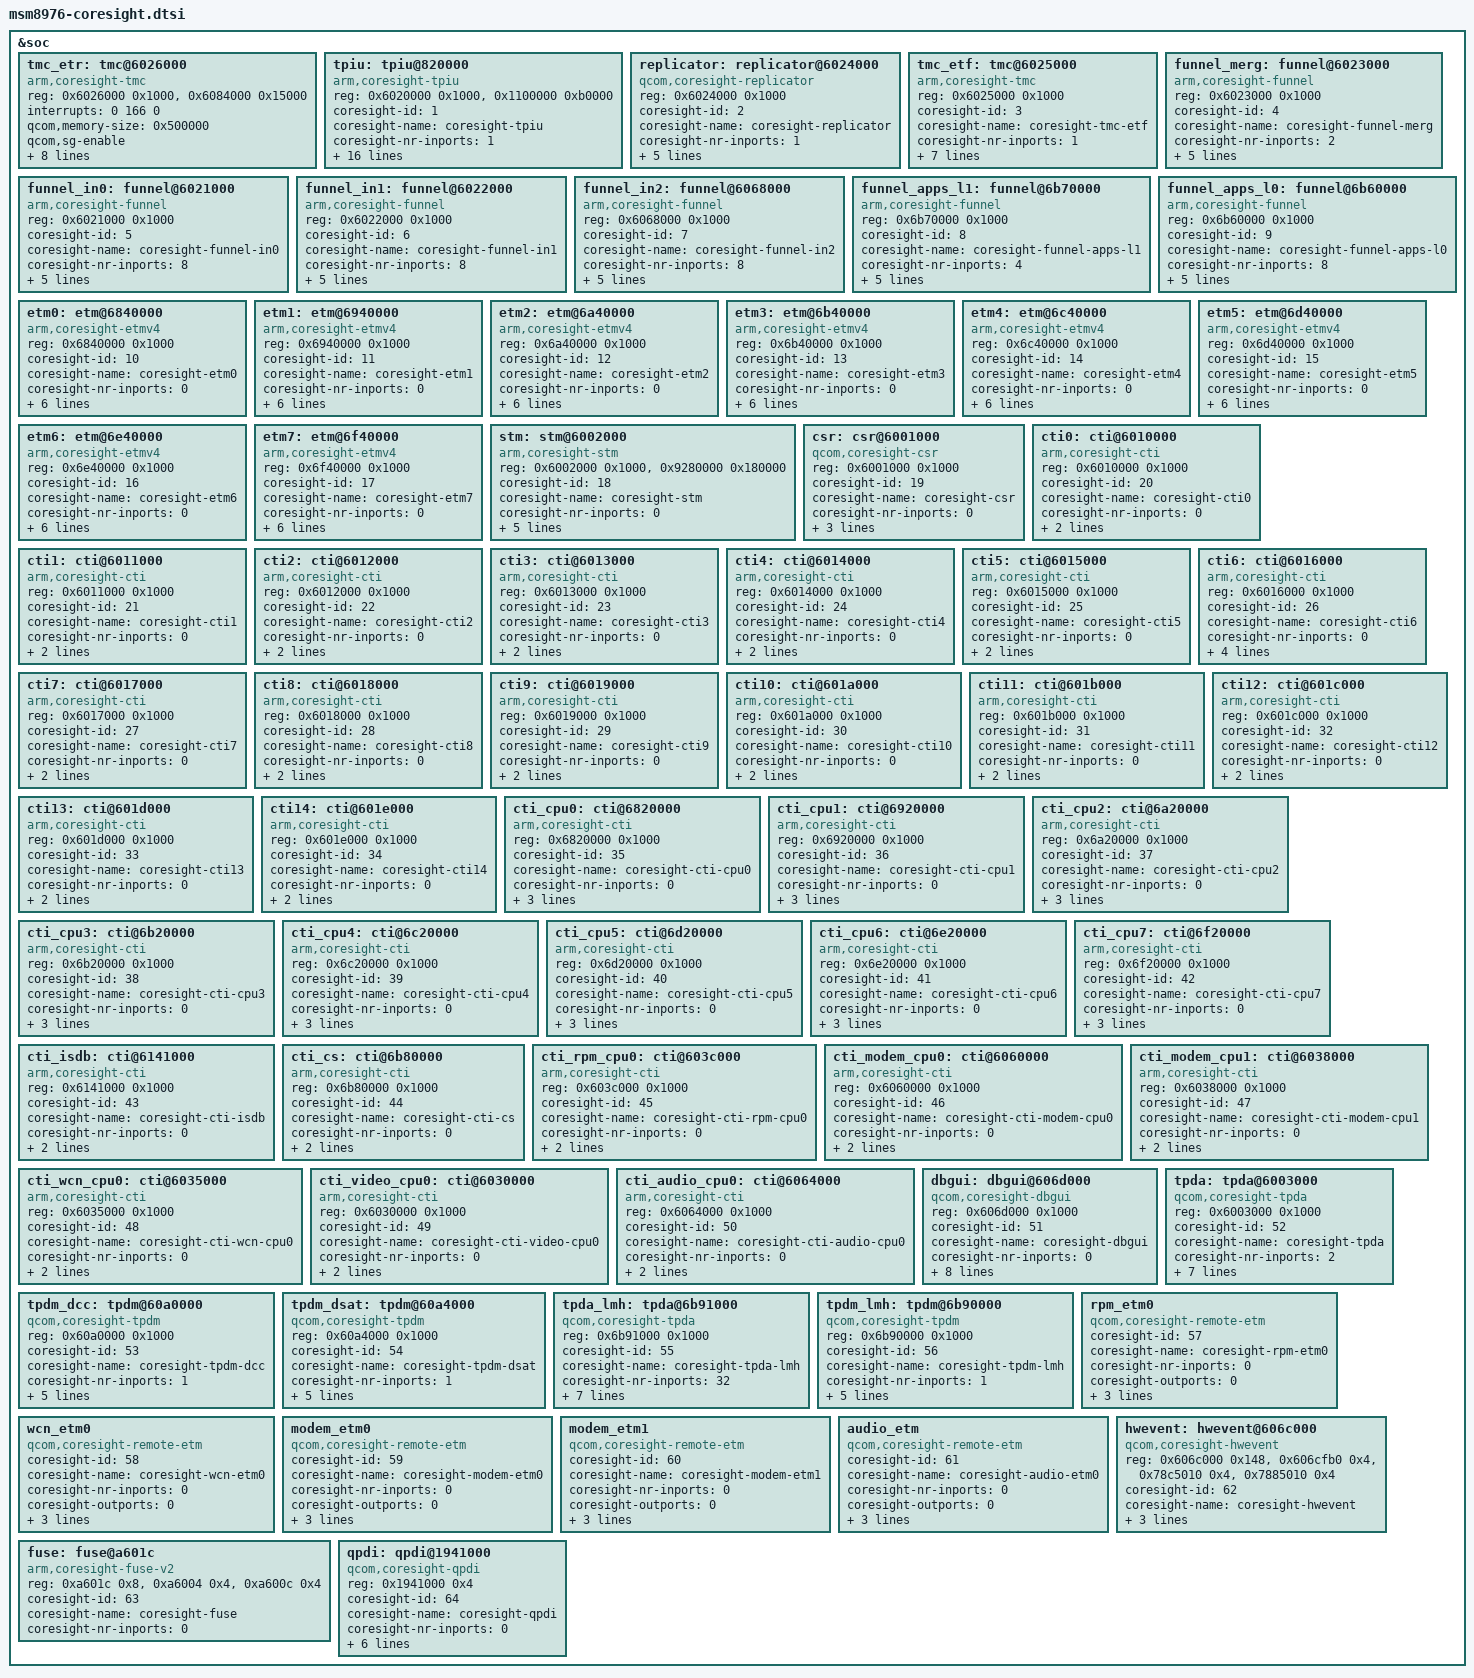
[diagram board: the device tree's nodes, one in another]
/* Copyright (c) 2015, The Linux Foundation. All rights reserved.
 *
 * This program is free software; you can redistribute it and/or modify
 * it under the terms of the GNU General Public License version 2 and
 * only version 2 as published by the Free Software Foundation.
 *
 * This program is distributed in the hope that it will be useful,
 * but WITHOUT ANY WARRANTY; without even the implied warranty of
 * MERCHANTABILITY or FITNESS FOR A PARTICULAR PURPOSE.  See the
 * GNU General Public License for more details.
 */

&soc {
	tmc_etr: tmc@6026000 {
		compatible = "arm,coresight-tmc";
		reg = <0x6026000 0x1000>,
		      <0x6084000 0x15000>;
		reg-names = "tmc-base", "bam-base";
		interrupts = <0 166 0>;
		interrupt-names = "byte-cntr-irq";

		qcom,memory-size = <0x500000>;
		qcom,sg-enable;
		coresight-default-sink;
		qcom,force-reg-dump;

		coresight-id = <0>;
		coresight-name = "coresight-tmc-etr";
		coresight-nr-inports = <1>;
		coresight-ctis = <&cti0 &cti8>;
		clocks = <&clock_gcc clk_qdss_clk>,
			 <&clock_gcc clk_qdss_a_clk>;
		clock-names = "core_clk", "core_a_clk";
	};

	tpiu: tpiu@820000 {
		compatible = "arm,coresight-tpiu";
		reg = <0x6020000 0x1000>,
		      <0x1100000 0xb0000>;
		reg-names = "tpiu-base", "nidnt-base";

		coresight-id = <1>;
		coresight-name = "coresight-tpiu";
		coresight-nr-inports = <1>;

		qcom,nidnthw;
		qcom,nidnt-swduart;
		qcom,nidnt-swdtrc;
		qcom,nidnt-jtag;
		qcom,nidnt-spmi;
		nidnt-gpio = <38>;
		nidnt-gpio-polarity = <1>;

		interrupts = <0 82 0>;
		interrupt-names = "nidnt-irq";

		vdd-supply = <&pm8950_l11>;
		qcom,vdd-voltage-level = <2950000 2950000>;
		qcom,vdd-current-level = <15000 400000>;

		vdd-io-supply = <&pm8950_l12>;
		qcom,vdd-io-voltage-level = <2950000 2950000>;
		qcom,vdd-io-current-level = <200 50000>;

		clocks = <&clock_gcc clk_qdss_clk>,
			 <&clock_gcc clk_qdss_a_clk>;
		clock-names = "core_clk", "core_a_clk";
	};

	replicator: replicator@6024000 {
		compatible = "qcom,coresight-replicator";
		reg = <0x6024000 0x1000>;
		reg-names = "replicator-base";

		coresight-id = <2>;
		coresight-name = "coresight-replicator";
		coresight-nr-inports = <1>;
		coresight-outports = <0 1>;
		coresight-child-list = <&tmc_etr &tpiu>;
		coresight-child-ports = <0 0>;
		clocks = <&clock_gcc clk_qdss_clk>,
			 <&clock_gcc clk_qdss_a_clk>;
		clock-names = "core_clk", "core_a_clk";
	};

	tmc_etf: tmc@6025000 {
		compatible = "arm,coresight-tmc";
		reg = <0x6025000 0x1000>;
		reg-names = "tmc-base";

		coresight-id = <3>;
		coresight-name = "coresight-tmc-etf";
		coresight-nr-inports = <1>;
		coresight-outports = <0>;
		coresight-child-list = <&replicator>;
		coresight-child-ports = <0>;
		coresight-ctis = <&cti0 &cti8>;
		qcom,force-reg-dump;

		clocks = <&clock_gcc clk_qdss_clk>,
			 <&clock_gcc clk_qdss_a_clk>;
		clock-names = "core_clk", "core_a_clk";
	};

	funnel_merg: funnel@6023000 {
		compatible = "arm,coresight-funnel";
		reg = <0x6023000 0x1000>;
		reg-names = "funnel-base";

		coresight-id = <4>;
		coresight-name = "coresight-funnel-merg";
		coresight-nr-inports = <2>;
		coresight-outports = <0>;
		coresight-child-list = <&tmc_etf>;
		coresight-child-ports = <0>;

		clocks = <&clock_gcc clk_qdss_clk>,
			 <&clock_gcc clk_qdss_a_clk>;
		clock-names = "core_clk", "core_a_clk";
	};

	funnel_in0: funnel@6021000 {
		compatible = "arm,coresight-funnel";
		reg = <0x6021000 0x1000>;
		reg-names = "funnel-base";

		coresight-id = <5>;
		coresight-name = "coresight-funnel-in0";
		coresight-nr-inports = <8>;
		coresight-outports = <0>;
		coresight-child-list = <&funnel_merg>;
		coresight-child-ports = <0>;

		clocks = <&clock_gcc clk_qdss_clk>,
			 <&clock_gcc clk_qdss_a_clk>;
		clock-names = "core_clk", "core_a_clk";
	};

	funnel_in1: funnel@6022000 {
		compatible = "arm,coresight-funnel";
		reg = <0x6022000 0x1000>;
		reg-names = "funnel-base";

		coresight-id = <6>;
		coresight-name = "coresight-funnel-in1";
		coresight-nr-inports = <8>;
		coresight-outports = <0>;
		coresight-child-list = <&funnel_merg>;
		coresight-child-ports = <1>;

		clocks = <&clock_gcc clk_qdss_clk>,
			 <&clock_gcc clk_qdss_a_clk>;
		clock-names = "core_clk", "core_a_clk";
	};

	funnel_in2: funnel@6068000 {
		compatible = "arm,coresight-funnel";
		reg = <0x6068000 0x1000>;
		reg-names = "funnel-base";

		coresight-id = <7>;
		coresight-name = "coresight-funnel-in2";
		coresight-nr-inports = <8>;
		coresight-outports = <0>;
		coresight-child-list = <&funnel_in0>;
		coresight-child-ports = <6>;

		clocks = <&clock_gcc clk_qdss_clk>,
			 <&clock_gcc clk_qdss_a_clk>;
		clock-names = "core_clk", "core_a_clk";
	};

	funnel_apps_l1: funnel@6b70000 {
		compatible = "arm,coresight-funnel";
		reg = <0x6b70000 0x1000>;
		reg-names = "funnel-base";

		coresight-id = <8>;
		coresight-name = "coresight-funnel-apps-l1";
		coresight-nr-inports = <4>;
		coresight-outports = <0>;
		coresight-child-list = <&funnel_in1>;
		coresight-child-ports = <6>;

		clocks = <&clock_gcc clk_qdss_clk>,
			 <&clock_gcc clk_qdss_a_clk>;
		clock-names = "core_clk", "core_a_clk";
	};

	funnel_apps_l0: funnel@6b60000 {
		compatible = "arm,coresight-funnel";
		reg = <0x6b60000 0x1000>;
		reg-names = "funnel-base";

		coresight-id = <9>;
		coresight-name = "coresight-funnel-apps-l0";
		coresight-nr-inports = <8>;
		coresight-outports = <0>;
		coresight-child-list = <&funnel_apps_l1>;
		coresight-child-ports = <0>;

		clocks = <&clock_gcc clk_qdss_clk>,
			 <&clock_gcc clk_qdss_a_clk>;
		clock-names = "core_clk", "core_a_clk";
	};

	etm0: etm@6840000 {
		compatible = "arm,coresight-etmv4";
		reg = <0x6840000 0x1000>;
		reg-names = "etm-base";

		coresight-id = <10>;
		coresight-name = "coresight-etm0";
		coresight-nr-inports = <0>;
		coresight-outports = <0>;
		coresight-child-list = <&funnel_apps_l0>;
		coresight-child-ports = <0>;
		coresight-etm-cpu = <&CPU0>;

		clocks = <&clock_gcc clk_qdss_clk>,
			 <&clock_gcc clk_qdss_a_clk>;
		clock-names = "core_clk", "core_a_clk";
	};

	etm1: etm@6940000 {
		compatible = "arm,coresight-etmv4";
		reg = <0x6940000 0x1000>;
		reg-names = "etm-base";

		coresight-id = <11>;
		coresight-name = "coresight-etm1";
		coresight-nr-inports = <0>;
		coresight-outports = <0>;
		coresight-child-list = <&funnel_apps_l0>;
		coresight-child-ports = <1>;
		coresight-etm-cpu = <&CPU1>;

		clocks = <&clock_gcc clk_qdss_clk>,
			 <&clock_gcc clk_qdss_a_clk>;
		clock-names = "core_clk", "core_a_clk";
	};

	etm2: etm@6a40000 {
		compatible = "arm,coresight-etmv4";
		reg = <0x6a40000 0x1000>;
		reg-names = "etm-base";

		coresight-id = <12>;
		coresight-name = "coresight-etm2";
		coresight-nr-inports = <0>;
		coresight-outports = <0>;
		coresight-child-list = <&funnel_apps_l0>;
		coresight-child-ports = <2>;
		coresight-etm-cpu = <&CPU2>;

		clocks = <&clock_gcc clk_qdss_clk>,
			 <&clock_gcc clk_qdss_a_clk>;
		clock-names = "core_clk", "core_a_clk";
	};

	etm3: etm@6b40000 {
		compatible = "arm,coresight-etmv4";
		reg = <0x6b40000 0x1000>;
		reg-names = "etm-base";

		coresight-id = <13>;
		coresight-name = "coresight-etm3";
		coresight-nr-inports = <0>;
		coresight-outports = <0>;
		coresight-child-list = <&funnel_apps_l0>;
		coresight-child-ports = <3>;
		coresight-etm-cpu = <&CPU3>;

		clocks = <&clock_gcc clk_qdss_clk>,
			 <&clock_gcc clk_qdss_a_clk>;
		clock-names = "core_clk", "core_a_clk";
	};

	etm4: etm@6c40000 {
		compatible = "arm,coresight-etmv4";
		reg = <0x6c40000 0x1000>;
		reg-names = "etm-base";

		coresight-id = <14>;
		coresight-name = "coresight-etm4";
		coresight-nr-inports = <0>;
		coresight-outports = <0>;
		coresight-child-list = <&funnel_apps_l0>;
		coresight-child-ports = <4>;
		coresight-etm-cpu = <&CPU4>;

		clocks = <&clock_gcc clk_qdss_clk>,
			 <&clock_gcc clk_qdss_a_clk>;
		clock-names = "core_clk", "core_a_clk";
	};

	etm5: etm@6d40000 {
		compatible = "arm,coresight-etmv4";
		reg = <0x6d40000 0x1000>;
		reg-names = "etm-base";

		coresight-id = <15>;
		coresight-name = "coresight-etm5";
		coresight-nr-inports = <0>;
		coresight-outports = <0>;
		coresight-child-list = <&funnel_apps_l0>;
		coresight-child-ports = <5>;
		coresight-etm-cpu = <&CPU5>;

		clocks = <&clock_gcc clk_qdss_clk>,
			 <&clock_gcc clk_qdss_a_clk>;
		clock-names = "core_clk", "core_a_clk";
	};

	etm6: etm@6e40000 {
		compatible = "arm,coresight-etmv4";
		reg = <0x6e40000 0x1000>;
		reg-names = "etm-base";

		coresight-id = <16>;
		coresight-name = "coresight-etm6";
		coresight-nr-inports = <0>;
		coresight-outports = <0>;
		coresight-child-list = <&funnel_apps_l0>;
		coresight-child-ports = <6>;
		coresight-etm-cpu = <&CPU6>;

		clocks = <&clock_gcc clk_qdss_clk>,
			 <&clock_gcc clk_qdss_a_clk>;
		clock-names = "core_clk", "core_a_clk";
	};

	etm7: etm@6f40000 {
		compatible = "arm,coresight-etmv4";
		reg = <0x6f40000 0x1000>;
		reg-names = "etm-base";

		coresight-id = <17>;
		coresight-name = "coresight-etm7";
		coresight-nr-inports = <0>;
		coresight-outports = <0>;
		coresight-child-list = <&funnel_apps_l0>;
		coresight-child-ports = <7>;
		coresight-etm-cpu = <&CPU7>;

		clocks = <&clock_gcc clk_qdss_clk>,
			 <&clock_gcc clk_qdss_a_clk>;
		clock-names = "core_clk", "core_a_clk";
	};

	stm: stm@6002000 {
		compatible = "arm,coresight-stm";
		reg = <0x6002000 0x1000>,
		      <0x9280000 0x180000>;
		reg-names = "stm-base", "stm-data-base";

		coresight-id = <18>;
		coresight-name = "coresight-stm";
		coresight-nr-inports = <0>;
		coresight-outports = <0>;
		coresight-child-list = <&funnel_in0>;
		coresight-child-ports = <7>;
		clocks = <&clock_gcc clk_qdss_clk>,
			 <&clock_gcc clk_qdss_a_clk>;
		clock-names = "core_clk", "core_a_clk";
	};

	csr: csr@6001000 {
		compatible = "qcom,coresight-csr";
		reg = <0x6001000 0x1000>;
		reg-names = "csr-base";

		coresight-id = <19>;
		coresight-name = "coresight-csr";
		coresight-nr-inports = <0>;

		qcom,blk-size = <1>;
		clocks = <&clock_gcc clk_qdss_clk>,
			 <&clock_gcc clk_qdss_a_clk>;
		clock-names = "core_clk", "core_a_clk";
	};

	cti0: cti@6010000 {
		compatible = "arm,coresight-cti";
		reg = <0x6010000 0x1000>;
		reg-names = "cti-base";

		coresight-id = <20>;
		coresight-name = "coresight-cti0";
		coresight-nr-inports = <0>;

		clocks = <&clock_gcc clk_qdss_clk>,
			 <&clock_gcc clk_qdss_a_clk>;
		clock-names = "core_clk", "core_a_clk";
	};

	cti1: cti@6011000 {
		compatible = "arm,coresight-cti";
		reg = <0x6011000 0x1000>;
		reg-names = "cti-base";

		coresight-id = <21>;
		coresight-name = "coresight-cti1";
		coresight-nr-inports = <0>;

		clocks = <&clock_gcc clk_qdss_clk>,
			 <&clock_gcc clk_qdss_a_clk>;
		clock-names = "core_clk", "core_a_clk";
	};

	cti2: cti@6012000 {
		compatible = "arm,coresight-cti";
		reg = <0x6012000 0x1000>;
		reg-names = "cti-base";

		coresight-id = <22>;
		coresight-name = "coresight-cti2";
		coresight-nr-inports = <0>;

		clocks = <&clock_gcc clk_qdss_clk>,
			 <&clock_gcc clk_qdss_a_clk>;
		clock-names = "core_clk", "core_a_clk";
	};

	cti3: cti@6013000 {
		compatible = "arm,coresight-cti";
		reg = <0x6013000 0x1000>;
		reg-names = "cti-base";

		coresight-id = <23>;
		coresight-name = "coresight-cti3";
		coresight-nr-inports = <0>;

		clocks = <&clock_gcc clk_qdss_clk>,
			 <&clock_gcc clk_qdss_a_clk>;
		clock-names = "core_clk", "core_a_clk";
	};

	cti4: cti@6014000 {
		compatible = "arm,coresight-cti";
		reg = <0x6014000 0x1000>;
		reg-names = "cti-base";

		coresight-id = <24>;
		coresight-name = "coresight-cti4";
		coresight-nr-inports = <0>;

		clocks = <&clock_gcc clk_qdss_clk>,
			 <&clock_gcc clk_qdss_a_clk>;
		clock-names = "core_clk", "core_a_clk";
	};

	cti5: cti@6015000 {
		compatible = "arm,coresight-cti";
		reg = <0x6015000 0x1000>;
		reg-names = "cti-base";

		coresight-id = <25>;
		coresight-name = "coresight-cti5";
		coresight-nr-inports = <0>;

		clocks = <&clock_gcc clk_qdss_clk>,
			 <&clock_gcc clk_qdss_a_clk>;
		clock-names = "core_clk", "core_a_clk";
	};

	cti6: cti@6016000 {
		compatible = "arm,coresight-cti";
		reg = <0x6016000 0x1000>;
		reg-names = "cti-base";

		coresight-id = <26>;
		coresight-name = "coresight-cti6";
		coresight-nr-inports = <0>;

		clocks = <&clock_gcc clk_qdss_clk>,
			 <&clock_gcc clk_qdss_a_clk>;
		clock-names = "core_clk", "core_a_clk";

		qcom,cti-gpio-trigout = <2>;
		pinctrl-names = "cti-trigout-pctrl";
		pinctrl-0 = <&trigout_b0>;
	};

	cti7: cti@6017000 {
		compatible = "arm,coresight-cti";
		reg = <0x6017000 0x1000>;
		reg-names = "cti-base";

		coresight-id = <27>;
		coresight-name = "coresight-cti7";
		coresight-nr-inports = <0>;

		clocks = <&clock_gcc clk_qdss_clk>,
			 <&clock_gcc clk_qdss_a_clk>;
		clock-names = "core_clk", "core_a_clk";
	};

	cti8: cti@6018000 {
		compatible = "arm,coresight-cti";
		reg = <0x6018000 0x1000>;
		reg-names = "cti-base";

		coresight-id = <28>;
		coresight-name = "coresight-cti8";
		coresight-nr-inports = <0>;

		clocks = <&clock_gcc clk_qdss_clk>,
			 <&clock_gcc clk_qdss_a_clk>;
		clock-names = "core_clk", "core_a_clk";
	};

	cti9: cti@6019000 {
		compatible = "arm,coresight-cti";
		reg = <0x6019000 0x1000>;
		reg-names = "cti-base";

		coresight-id = <29>;
		coresight-name = "coresight-cti9";
		coresight-nr-inports = <0>;

		clocks = <&clock_gcc clk_qdss_clk>,
			 <&clock_gcc clk_qdss_a_clk>;
		clock-names = "core_clk", "core_a_clk";
	};

	cti10: cti@601a000 {
		compatible = "arm,coresight-cti";
		reg = <0x601a000 0x1000>;
		reg-names = "cti-base";

		coresight-id = <30>;
		coresight-name = "coresight-cti10";
		coresight-nr-inports = <0>;

		clocks = <&clock_gcc clk_qdss_clk>,
			 <&clock_gcc clk_qdss_a_clk>;
		clock-names = "core_clk", "core_a_clk";
	};

	cti11: cti@601b000 {
		compatible = "arm,coresight-cti";
		reg = <0x601b000 0x1000>;
		reg-names = "cti-base";

		coresight-id = <31>;
		coresight-name = "coresight-cti11";
		coresight-nr-inports = <0>;

		clocks = <&clock_gcc clk_qdss_clk>,
			 <&clock_gcc clk_qdss_a_clk>;
		clock-names = "core_clk", "core_a_clk";
	};

	cti12: cti@601c000 {
		compatible = "arm,coresight-cti";
		reg = <0x601c000 0x1000>;
		reg-names = "cti-base";

		coresight-id = <32>;
		coresight-name = "coresight-cti12";
		coresight-nr-inports = <0>;

		clocks = <&clock_gcc clk_qdss_clk>,
			 <&clock_gcc clk_qdss_a_clk>;
		clock-names = "core_clk", "core_a_clk";
	};

	cti13: cti@601d000 {
		compatible = "arm,coresight-cti";
		reg = <0x601d000 0x1000>;
		reg-names = "cti-base";

		coresight-id = <33>;
		coresight-name = "coresight-cti13";
		coresight-nr-inports = <0>;

		clocks = <&clock_gcc clk_qdss_clk>,
			 <&clock_gcc clk_qdss_a_clk>;
		clock-names = "core_clk", "core_a_clk";
	};

	cti14: cti@601e000 {
		compatible = "arm,coresight-cti";
		reg = <0x601e000 0x1000>;
		reg-names = "cti-base";

		coresight-id = <34>;
		coresight-name = "coresight-cti14";
		coresight-nr-inports = <0>;

		clocks = <&clock_gcc clk_qdss_clk>,
			 <&clock_gcc clk_qdss_a_clk>;
		clock-names = "core_clk", "core_a_clk";
	};

	cti_cpu0: cti@6820000 {
		compatible = "arm,coresight-cti";
		reg = <0x6820000 0x1000>;
		reg-names = "cti-base";

		coresight-id = <35>;
		coresight-name = "coresight-cti-cpu0";
		coresight-nr-inports = <0>;
		coresight-cti-cpu = <&CPU0>;

		clocks = <&clock_gcc clk_qdss_clk>,
			 <&clock_gcc clk_qdss_a_clk>;
		clock-names = "core_clk", "core_a_clk";
	};

	cti_cpu1: cti@6920000 {
		compatible = "arm,coresight-cti";
		reg = <0x6920000 0x1000>;
		reg-names = "cti-base";

		coresight-id = <36>;
		coresight-name = "coresight-cti-cpu1";
		coresight-nr-inports = <0>;
		coresight-cti-cpu = <&CPU1>;

		clocks = <&clock_gcc clk_qdss_clk>,
			 <&clock_gcc clk_qdss_a_clk>;
		clock-names = "core_clk", "core_a_clk";
	};

	cti_cpu2: cti@6a20000 {
		compatible = "arm,coresight-cti";
		reg = <0x6a20000 0x1000>;
		reg-names = "cti-base";

		coresight-id = <37>;
		coresight-name = "coresight-cti-cpu2";
		coresight-nr-inports = <0>;
		coresight-cti-cpu = <&CPU2>;

		clocks = <&clock_gcc clk_qdss_clk>,
			 <&clock_gcc clk_qdss_a_clk>;
		clock-names = "core_clk", "core_a_clk";
	};

	cti_cpu3: cti@6b20000 {
		compatible = "arm,coresight-cti";
		reg = <0x6b20000 0x1000>;
		reg-names = "cti-base";

		coresight-id = <38>;
		coresight-name = "coresight-cti-cpu3";
		coresight-nr-inports = <0>;
		coresight-cti-cpu = <&CPU3>;

		clocks = <&clock_gcc clk_qdss_clk>,
			 <&clock_gcc clk_qdss_a_clk>;
		clock-names = "core_clk", "core_a_clk";
	};

	cti_cpu4: cti@6c20000 {
		compatible = "arm,coresight-cti";
		reg = <0x6c20000 0x1000>;
		reg-names = "cti-base";

		coresight-id = <39>;
		coresight-name = "coresight-cti-cpu4";
		coresight-nr-inports = <0>;
		coresight-cti-cpu = <&CPU4>;

		clocks = <&clock_gcc clk_qdss_clk>,
			 <&clock_gcc clk_qdss_a_clk>;
		clock-names = "core_clk", "core_a_clk";
	};

	cti_cpu5: cti@6d20000 {
		compatible = "arm,coresight-cti";
		reg = <0x6d20000 0x1000>;
		reg-names = "cti-base";

		coresight-id = <40>;
		coresight-name = "coresight-cti-cpu5";
		coresight-nr-inports = <0>;
		coresight-cti-cpu = <&CPU5>;

		clocks = <&clock_gcc clk_qdss_clk>,
			 <&clock_gcc clk_qdss_a_clk>;
		clock-names = "core_clk", "core_a_clk";
	};

	cti_cpu6: cti@6e20000 {
		compatible = "arm,coresight-cti";
		reg = <0x6e20000 0x1000>;
		reg-names = "cti-base";

		coresight-id = <41>;
		coresight-name = "coresight-cti-cpu6";
		coresight-nr-inports = <0>;
		coresight-cti-cpu = <&CPU6>;

		clocks = <&clock_gcc clk_qdss_clk>,
			 <&clock_gcc clk_qdss_a_clk>;
		clock-names = "core_clk", "core_a_clk";
	};

	cti_cpu7: cti@6f20000 {
		compatible = "arm,coresight-cti";
		reg = <0x6f20000 0x1000>;
		reg-names = "cti-base";

		coresight-id = <42>;
		coresight-name = "coresight-cti-cpu7";
		coresight-nr-inports = <0>;
		coresight-cti-cpu = <&CPU7>;

		clocks = <&clock_gcc clk_qdss_clk>,
			 <&clock_gcc clk_qdss_a_clk>;
		clock-names = "core_clk", "core_a_clk";
	};

	cti_isdb: cti@6141000 {
		compatible = "arm,coresight-cti";
		reg = <0x6141000 0x1000>;
		reg-names = "cti-base";

		coresight-id = <43>;
		coresight-name = "coresight-cti-isdb";
		coresight-nr-inports = <0>;

		clocks = <&clock_gcc clk_qdss_clk>,
			 <&clock_gcc clk_qdss_a_clk>;
		clock-names = "core_clk", "core_a_clk";
	};

	cti_cs: cti@6b80000 {
		compatible = "arm,coresight-cti";
		reg = <0x6b80000 0x1000>;
		reg-names = "cti-base";

		coresight-id = <44>;
		coresight-name = "coresight-cti-cs";
		coresight-nr-inports = <0>;

		clocks = <&clock_gcc clk_qdss_clk>,
			 <&clock_gcc clk_qdss_a_clk>;
		clock-names = "core_clk", "core_a_clk";
	};

	cti_rpm_cpu0: cti@603c000 {
		compatible = "arm,coresight-cti";
		reg = <0x603c000 0x1000>;
		reg-names = "cti-base";

		coresight-id = <45>;
		coresight-name = "coresight-cti-rpm-cpu0";
		coresight-nr-inports = <0>;

		clocks = <&clock_gcc clk_qdss_clk>,
			 <&clock_gcc clk_qdss_a_clk>;
		clock-names = "core_clk", "core_a_clk";
	};

	cti_modem_cpu0: cti@6060000 {
		compatible = "arm,coresight-cti";
		reg = <0x6060000 0x1000>;
		reg-names = "cti-base";

		coresight-id = <46>;
		coresight-name = "coresight-cti-modem-cpu0";
		coresight-nr-inports = <0>;

		clocks = <&clock_gcc clk_qdss_clk>,
			 <&clock_gcc clk_qdss_a_clk>;
		clock-names = "core_clk", "core_a_clk";
	};

	cti_modem_cpu1: cti@6038000 {
		compatible = "arm,coresight-cti";
		reg = <0x6038000 0x1000>;
		reg-names = "cti-base";

		coresight-id = <47>;
		coresight-name = "coresight-cti-modem-cpu1";
		coresight-nr-inports = <0>;

		clocks = <&clock_gcc clk_qdss_clk>,
			 <&clock_gcc clk_qdss_a_clk>;
		clock-names = "core_clk", "core_a_clk";
	};

	cti_wcn_cpu0: cti@6035000 {
		compatible = "arm,coresight-cti";
		reg = <0x6035000 0x1000>;
		reg-names = "cti-base";

		coresight-id = <48>;
		coresight-name = "coresight-cti-wcn-cpu0";
		coresight-nr-inports = <0>;

		clocks = <&clock_gcc clk_qdss_clk>,
			 <&clock_gcc clk_qdss_a_clk>;
		clock-names = "core_clk", "core_a_clk";
	};

	cti_video_cpu0: cti@6030000 {
		compatible = "arm,coresight-cti";
		reg = <0x6030000 0x1000>;
		reg-names = "cti-base";

		coresight-id = <49>;
		coresight-name = "coresight-cti-video-cpu0";
		coresight-nr-inports = <0>;

		clocks = <&clock_gcc clk_qdss_clk>,
			 <&clock_gcc clk_qdss_a_clk>;
		clock-names = "core_clk", "core_a_clk";
	};

	cti_audio_cpu0: cti@6064000 {
		compatible = "arm,coresight-cti";
		reg = <0x6064000 0x1000>;
		reg-names = "cti-base";

		coresight-id = <50>;
		coresight-name = "coresight-cti-audio-cpu0";
		coresight-nr-inports = <0>;
		clocks = <&clock_gcc clk_qdss_clk>,
			 <&clock_gcc clk_qdss_a_clk>;
		clock-names = "core_clk", "core_a_clk";
	};

	dbgui: dbgui@606d000 {
		compatible = "qcom,coresight-dbgui";
		reg = <0x606d000 0x1000>;
		reg-names = "dbgui-base";

		coresight-id = <51>;
		coresight-name = "coresight-dbgui";
		coresight-nr-inports = <0>;
		coresight-outports = <0>;
		coresight-child-list = <&funnel_in1>;
		coresight-child-ports = <3>;

		qcom,dbgui-addr-offset = <0x30>;
		qcom,dbgui-data-offset = <0x130>;
		qcom,dbgui-size = <64>;

		clocks = <&clock_gcc clk_qdss_clk>,
			 <&clock_gcc clk_qdss_a_clk>;
		clock-names = "core_clk", "core_a_clk";
	};

	tpda: tpda@6003000 {
		compatible = "qcom,coresight-tpda";
		reg = <0x6003000 0x1000>;
		reg-names = "tpda-base";

		coresight-id = <52>;
		coresight-name = "coresight-tpda";
		coresight-nr-inports = <2>;
		coresight-outports = <0>;
		coresight-child-list = <&funnel_in0>;
		coresight-child-ports = <3>;

		qcom,tpda-atid = <64>;
		qcom,cmb-elem-size = <0 32>;

		clocks = <&clock_gcc clk_qdss_clk>,
			 <&clock_gcc clk_qdss_a_clk>;
		clock-names = "core_clk", "core_a_clk";
	};

	tpdm_dcc: tpdm@60a0000 {
		compatible = "qcom,coresight-tpdm";
		reg = <0x60a0000 0x1000>;
		reg-names = "tpdm-base";

		coresight-id = <53>;
		coresight-name = "coresight-tpdm-dcc";
		coresight-nr-inports = <1>;
		coresight-outports = <0>;
		coresight-child-list = <&tpda>;
		coresight-child-ports = <0>;

		clocks = <&clock_gcc clk_qdss_clk>,
			 <&clock_gcc clk_qdss_a_clk>;
		clock-names = "core_clk", "core_a_clk";
	};

	tpdm_dsat: tpdm@60a4000 {
		compatible = "qcom,coresight-tpdm";
		reg = <0x60a4000 0x1000>;
		reg-names = "tpdm-base";

		coresight-id = <54>;
		coresight-name = "coresight-tpdm-dsat";
		coresight-nr-inports = <1>;
		coresight-outports = <0>;
		coresight-child-list = <&tpda>;
		coresight-child-ports = <1>;

		clocks = <&clock_gcc clk_qdss_clk>,
			 <&clock_gcc clk_qdss_a_clk>;
		clock-names = "core_clk", "core_a_clk";
	};

	tpda_lmh: tpda@6b91000 {
		compatible = "qcom,coresight-tpda";
		reg = <0x6b91000 0x1000>;
		reg-names = "tpda-base";

		coresight-id = <55>;
		coresight-name = "coresight-tpda-lmh";
		coresight-nr-inports = <32>;
		coresight-outports = <0>;
		coresight-child-list = <&funnel_apps_l1>;
		coresight-child-ports = <1>;

		qcom,tpda-atid = <65>;
		qcom,cmb-elem-size = <0 64>;

		clocks = <&clock_gcc clk_qdss_clk>,
			 <&clock_gcc clk_qdss_a_clk>;
		clock-names = "core_clk", "core_a_clk";
	};

	tpdm_lmh: tpdm@6b90000 {
		compatible = "qcom,coresight-tpdm";
		reg = <0x6b90000 0x1000>;
		reg-names = "tpdm-base";

		coresight-id = <56>;
		coresight-name = "coresight-tpdm-lmh";
		coresight-nr-inports = <1>;
		coresight-outports = <0>;
		coresight-child-list = <&tpda_lmh>;
		coresight-child-ports = <0>;

		clocks = <&clock_gcc clk_qdss_clk>,
			 <&clock_gcc clk_qdss_a_clk>;
		clock-names = "core_clk", "core_a_clk";
	};

	rpm_etm0 {
		compatible = "qcom,coresight-remote-etm";

		coresight-id = <57>;
		coresight-name = "coresight-rpm-etm0";
		coresight-nr-inports = <0>;
		coresight-outports = <0>;
		coresight-child-list = <&funnel_in0>;
		coresight-child-ports = <0>;

		qcom,inst-id = <4>;
	};

	wcn_etm0 {
		compatible = "qcom,coresight-remote-etm";

		coresight-id = <58>;
		coresight-name = "coresight-wcn-etm0";
		coresight-nr-inports = <0>;
		coresight-outports = <0>;
		coresight-child-list = <&funnel_in1>;
		coresight-child-ports = <0>;

		qcom,inst-id = <3>;
	};

	modem_etm0 {
		compatible = "qcom,coresight-remote-etm";

		coresight-id = <59>;
		coresight-name = "coresight-modem-etm0";
		coresight-nr-inports = <0>;
		coresight-outports = <0>;
		coresight-child-list = <&funnel_in1>;
		coresight-child-ports = <7>;

		qcom,inst-id = <2>;
	};

	modem_etm1 {
		compatible = "qcom,coresight-remote-etm";

		coresight-id = <60>;
		coresight-name = "coresight-modem-etm1";
		coresight-nr-inports = <0>;
		coresight-outports = <0>;
		coresight-child-list = <&funnel_in0>;
		coresight-child-ports = <1>;

		qcom,inst-id = <11>;
	};

	audio_etm {
		compatible = "qcom,coresight-remote-etm";

		coresight-id = <61>;
		coresight-name = "coresight-audio-etm0";
		coresight-nr-inports = <0>;
		coresight-outports = <0>;
		coresight-child-list = <&funnel_in0>;
		coresight-child-ports = <2>;

		qcom,inst-id = <5>;
	};

	hwevent: hwevent@606c000 {
		compatible = "qcom,coresight-hwevent";
		reg = <0x606c000 0x148>,
		      <0x606cfb0 0x4>,
		      <0x78c5010 0x4>,
		      <0x7885010 0x4>;
		reg-names = "wrapper-mux", "wrapper-lockaccess", "usbbam-mux",
		            "blsp-mux";
		coresight-id = <62>;
		coresight-name = "coresight-hwevent";
		coresight-nr-inports = <0>;

		clocks = <&clock_gcc clk_qdss_clk>,
			 <&clock_gcc clk_qdss_a_clk>;
		clock-names = "core_clk", "core_a_clk";
	};

	fuse: fuse@a601c {
		compatible = "arm,coresight-fuse-v2";
		reg = <0xa601c 0x8>,
		      <0xa6004 0x4>,
		      <0xa600c 0x4>;
		reg-names = "fuse-base", "nidnt-fuse-base", "qpdi-fuse-base";

		coresight-id = <63>;
		coresight-name = "coresight-fuse";
		coresight-nr-inports = <0>;
	};

	qpdi: qpdi@1941000 {
		compatible = "qcom,coresight-qpdi";
		reg = <0x1941000 0x4>;
		reg-names = "qpdi-base";

		coresight-id = <64>;
		coresight-name = "coresight-qpdi";
		coresight-nr-inports = <0>;

		vdd-supply = <&pm8950_l11>;
		qcom,vdd-voltage-level = <2800000 2950000>;
		qcom,vdd-current-level = <15000 400000>;

		vdd-io-supply = <&pm8950_l12>;
		qcom,vdd-io-voltage-level = <1800000 2950000>;
		qcom,vdd-io-current-level = <200 50000>;
	};
};

